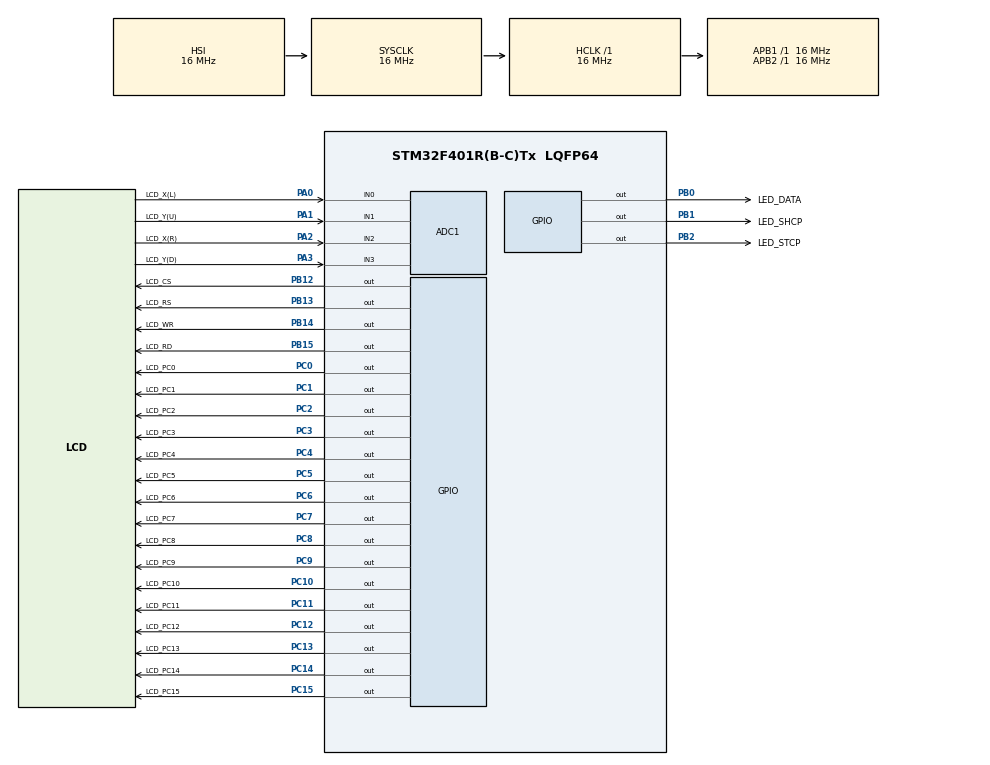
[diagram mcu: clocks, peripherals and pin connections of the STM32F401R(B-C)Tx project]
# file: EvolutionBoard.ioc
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ADC1.Channel-0\#ChannelRegularConversion=ADC_CHANNEL_0
ADC1.NbrOfConversionFlag=1
ADC1.Rank-0\#ChannelRegularConversion=1
ADC1.SamplingTime-0\#ChannelRegularConversion=ADC_SAMPLETIME_3CYCLES
ADC1.master=1
Dma.ADC1.0.Direction=DMA_PERIPH_TO_MEMORY
Dma.ADC1.0.FIFOMode=DMA_FIFOMODE_DISABLE
Dma.ADC1.0.Instance=DMA2_Stream0
Dma.ADC1.0.MemDataAlignment=DMA_MDATAALIGN_HALFWORD
Dma.ADC1.0.MemInc=DMA_MINC_ENABLE
Dma.ADC1.0.Mode=DMA_NORMAL
Dma.ADC1.0.PeriphDataAlignment=DMA_PDATAALIGN_HALFWORD
Dma.ADC1.0.PeriphInc=DMA_PINC_DISABLE
Dma.ADC1.0.Priority=DMA_PRIORITY_LOW
Dma.MEMTOMEM.1.Direction=DMA_MEMORY_TO_MEMORY
Dma.MEMTOMEM.1.FIFOMode=DMA_FIFOMODE_ENABLE
Dma.MEMTOMEM.1.FIFOThreshold=DMA_FIFO_THRESHOLD_FULL
Dma.MEMTOMEM.1.Instance=DMA2_Stream1
Dma.MEMTOMEM.1.MemBurst=DMA_MBURST_SINGLE
Dma.MEMTOMEM.1.MemDataAlignment=DMA_MDATAALIGN_BYTE
Dma.MEMTOMEM.1.MemInc=DMA_MINC_ENABLE
Dma.MEMTOMEM.1.Mode=DMA_NORMAL
Dma.MEMTOMEM.1.PeriphBurst=DMA_PBURST_SINGLE
Dma.MEMTOMEM.1.PeriphDataAlignment=DMA_PDATAALIGN_BYTE
Dma.MEMTOMEM.1.PeriphInc=DMA_PINC_ENABLE
Dma.MEMTOMEM.1.Priority=DMA_PRIORITY_LOW
Dma.Request0=ADC1
Dma.Request1=MEMTOMEM
Mcu.Family=STM32F4
Mcu.Name=STM32F401R(B-C)Tx
Mcu.Package=LQFP64
NVIC.DMA2_Stream0_IRQn=true\:5\:0\:false\:false\:true\:true\:false
NVIC.PriorityGroup=NVIC_PRIORITYGROUP_4
PA0-WKUP.GPIO_Label=LCD_X(L)
PA0-WKUP.Signal=ADCx_IN0
PA1.GPIO_Label=LCD_Y(U)
PA1.Signal=ADCx_IN1
PA13.Mode=Serial_Wire
PA13.Signal=SYS_JTMS-SWDIO
PA14.Mode=Serial_Wire
PA14.Signal=SYS_JTCK-SWCLK
PA2.GPIO_Label=LCD_X(R)
PA2.Signal=ADCx_IN2
PA3.GPIO_Label=LCD_Y(D)
PA3.Signal=ADCx_IN3
PB0.GPIO_Label=LED_DATA
PB0.Signal=GPIO_Output
PB1.GPIO_Label=LED_SHCP
PB1.Signal=GPIO_Output
PB12.GPIO_Label=LCD_CS
PB12.Signal=GPIO_Output
PB13.GPIO_Label=LCD_RS
PB13.Signal=GPIO_Output
PB14.GPIO_Label=LCD_WR
PB14.Signal=GPIO_Output
PB15.GPIO_Label=LCD_RD
PB15.Signal=GPIO_Output
PB2.GPIO_Label=LED_STCP
PB2.Signal=GPIO_Output
PC0.GPIO_Label=LCD_PC0
PC0.Signal=GPIO_Output
PC1.GPIO_Label=LCD_PC1
PC1.Signal=GPIO_Output
PC10.GPIO_Label=LCD_PC10
PC10.Signal=GPIO_Output
PC11.GPIO_Label=LCD_PC11
PC11.Signal=GPIO_Output
PC12.GPIO_Label=LCD_PC12
PC12.Signal=GPIO_Output
PC13-ANTI_TAMP.GPIO_Label=LCD_PC13
PC13-ANTI_TAMP.Signal=GPIO_Output
PC14-OSC32_IN.GPIO_Label=LCD_PC14
PC14-OSC32_IN.Signal=GPIO_Output
PC15-OSC32_OUT.GPIO_Label=LCD_PC15
PC15-OSC32_OUT.Signal=GPIO_Output
PC2.GPIO_Label=LCD_PC2
PC2.Signal=GPIO_Output
PC3.GPIO_Label=LCD_PC3
PC3.Signal=GPIO_Output
PC4.GPIO_Label=LCD_PC4
PC4.Signal=GPIO_Output
PC5.GPIO_Label=LCD_PC5
PC5.Signal=GPIO_Output
PC6.GPIO_Label=LCD_PC6
PC6.Signal=GPIO_Output
PC7.GPIO_Label=LCD_PC7
PC7.Signal=GPIO_Output
PC8.GPIO_Label=LCD_PC8
PC8.Signal=GPIO_Output
PC9.GPIO_Label=LCD_PC9
PC9.Signal=GPIO_Output
PH0\ -\ OSC_IN.Mode=HSE-External-Oscillator
PH0\ -\ OSC_IN.Signal=RCC_OSC_IN
PH1\ -\ OSC_OUT.Mode=HSE-External-Oscillator
PH1\ -\ OSC_OUT.Signal=RCC_OSC_OUT
ProjectManager.HeapSize=0x200
ProjectManager.StackSize=0x400
ProjectManager.TargetToolchain=TrueSTUDIO
RCC.48MHZClocksFreq_Value=48000000
RCC.AHBFreq_Value=16000000
RCC.APB1Freq_Value=16000000
RCC.APB2Freq_Value=16000000
RCC.CortexFreq_Value=16000000
RCC.HSE_VALUE=8000000
RCC.HSI_VALUE=16000000
RCC.LSE_VALUE=32768
RCC.PLLM=8
RCC.PLLN=240
RCC.PLLQ=5
RCC.PLLSourceVirtual=RCC_PLLSOURCE_HSE
RCC.SYSCLKFreq_VALUE=16000000
RCC.VCOOutputFreq_Value=240000000
SH.ADCx_IN0.0=ADC1_IN0,IN0
SH.ADCx_IN1.0=ADC1_IN1,IN1
SH.ADCx_IN2.0=ADC1_IN2,IN2
SH.ADCx_IN3.0=ADC1_IN3,IN3
board=custom

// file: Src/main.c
/* USER CODE BEGIN Header */
/**
  ******************************************************************************
  * @file           : main.c
  * @brief          : Main program body
  ******************************************************************************
  * @attention
  *
  * <h2><center>&copy; Copyright (c) 2019 STMicroelectronics.
  * All rights reserved.</center></h2>
  *
  * This software component is licensed by ST under BSD 3-Clause license,
  * the "License"; You may not use this file except in compliance with the
  * License. You may obtain a copy of the License at:
  *                        opensource.org/licenses/BSD-3-Clause
  *
  ******************************************************************************
  */
/* USER CODE END Header */

#include "main.h"

/* USER CODE BEGIN Includes */

#include "MainCpp.h"

/* USER CODE END Includes */

ADC_HandleTypeDef hadc1;
DMA_HandleTypeDef hdma_adc1;

DMA_HandleTypeDef hdma_memtomem_dma2_stream1;

void SystemClock_Config(void);
static void MX_GPIO_Init(void);
static void MX_DMA_Init(void);
static void MX_ADC1_Init(void);

/* USER CODE BEGIN 0 */

void MainCpp (void);

/* USER CODE END 0 */

int main(void)
{

  /* MCU Configuration--------------------------------------------------------*/

  /* Reset of all peripherals, Initializes the Flash interface and the Systick. */
  HAL_Init();

  /* Configure the system clock */
  SystemClock_Config();

  /* Initialize all configured peripherals */
  MX_GPIO_Init();
  MX_DMA_Init();
  MX_ADC1_Init();

  /* Infinite loop */
  while (1)
  {

    /* USER CODE BEGIN 3 */

	  MainCpp ();
  }
  /* USER CODE END 3 */
}

void SystemClock_Config(void)
{
  RCC_OscInitTypeDef RCC_OscInitStruct = {0};
  RCC_ClkInitTypeDef RCC_ClkInitStruct = {0};

  /** Configure the main internal regulator output voltage
  */
  __HAL_RCC_PWR_CLK_ENABLE();
  __HAL_PWR_VOLTAGESCALING_CONFIG(PWR_REGULATOR_VOLTAGE_SCALE2);
  /** Initializes the CPU, AHB and APB busses clocks
  */
  RCC_OscInitStruct.OscillatorType = RCC_OSCILLATORTYPE_HSI;
  RCC_OscInitStruct.HSIState = RCC_HSI_ON;
  RCC_OscInitStruct.HSICalibrationValue = RCC_HSICALIBRATION_DEFAULT;
  RCC_OscInitStruct.PLL.PLLState = RCC_PLL_NONE;
  if (HAL_RCC_OscConfig(&RCC_OscInitStruct) != HAL_OK)
  {
    Error_Handler();
  }
  /** Initializes the CPU, AHB and APB busses clocks
  */
  RCC_ClkInitStruct.ClockType = RCC_CLOCKTYPE_HCLK|RCC_CLOCKTYPE_SYSCLK
                              |RCC_CLOCKTYPE_PCLK1|RCC_CLOCKTYPE_PCLK2;
  RCC_ClkInitStruct.SYSCLKSource = RCC_SYSCLKSOURCE_HSI;
  RCC_ClkInitStruct.AHBCLKDivider = RCC_SYSCLK_DIV1;
  RCC_ClkInitStruct.APB1CLKDivider = RCC_HCLK_DIV1;
  RCC_ClkInitStruct.APB2CLKDivider = RCC_HCLK_DIV1;

  if (HAL_RCC_ClockConfig(&RCC_ClkInitStruct, FLASH_LATENCY_0) != HAL_OK)
  {
    Error_Handler();
  }
}

static void MX_ADC1_Init(void)
{

  ADC_ChannelConfTypeDef sConfig = {0};

  /** Configure the global features of the ADC (Clock, Resolution, Data Alignment and number of conversion)
  */
  hadc1.Instance = ADC1;
  hadc1.Init.ClockPrescaler = ADC_CLOCK_SYNC_PCLK_DIV2;
  hadc1.Init.Resolution = ADC_RESOLUTION_12B;
  hadc1.Init.ScanConvMode = DISABLE;
  hadc1.Init.ContinuousConvMode = DISABLE;
  hadc1.Init.DiscontinuousConvMode = DISABLE;
  hadc1.Init.ExternalTrigConvEdge = ADC_EXTERNALTRIGCONVEDGE_NONE;
  hadc1.Init.ExternalTrigConv = ADC_SOFTWARE_START;
  hadc1.Init.DataAlign = ADC_DATAALIGN_RIGHT;
  hadc1.Init.NbrOfConversion = 1;
  hadc1.Init.DMAContinuousRequests = DISABLE;
  hadc1.Init.EOCSelection = ADC_EOC_SINGLE_CONV;
  if (HAL_ADC_Init(&hadc1) != HAL_OK)
  {
    Error_Handler();
  }
  /** Configure for the selected ADC regular channel its corresponding rank in the sequencer and its sample time.
  */
  sConfig.Channel = ADC_CHANNEL_0;
  sConfig.Rank = 1;
  sConfig.SamplingTime = ADC_SAMPLETIME_3CYCLES;
  if (HAL_ADC_ConfigChannel(&hadc1, &sConfig) != HAL_OK)
  {
    Error_Handler();
  }

}

static void MX_DMA_Init(void)
{

  /* DMA controller clock enable */
  __HAL_RCC_DMA2_CLK_ENABLE();

  /* Configure DMA request hdma_memtomem_dma2_stream1 on DMA2_Stream1 */
  hdma_memtomem_dma2_stream1.Instance = DMA2_Stream1;
  hdma_memtomem_dma2_stream1.Init.Channel = DMA_CHANNEL_0;
  hdma_memtomem_dma2_stream1.Init.Direction = DMA_MEMORY_TO_MEMORY;
  hdma_memtomem_dma2_stream1.Init.PeriphInc = DMA_PINC_ENABLE;
  hdma_memtomem_dma2_stream1.Init.MemInc = DMA_MINC_ENABLE;
  hdma_memtomem_dma2_stream1.Init.PeriphDataAlignment = DMA_PDATAALIGN_BYTE;
  hdma_memtomem_dma2_stream1.Init.MemDataAlignment = DMA_MDATAALIGN_BYTE;
  hdma_memtomem_dma2_stream1.Init.Mode = DMA_NORMAL;
  hdma_memtomem_dma2_stream1.Init.Priority = DMA_PRIORITY_LOW;
  hdma_memtomem_dma2_stream1.Init.FIFOMode = DMA_FIFOMODE_ENABLE;
  hdma_memtomem_dma2_stream1.Init.FIFOThreshold = DMA_FIFO_THRESHOLD_FULL;
  hdma_memtomem_dma2_stream1.Init.MemBurst = DMA_MBURST_SINGLE;
  hdma_memtomem_dma2_stream1.Init.PeriphBurst = DMA_PBURST_SINGLE;
  if (HAL_DMA_Init(&hdma_memtomem_dma2_stream1) != HAL_OK)
  {
    Error_Handler( );
  }

  /* DMA interrupt init */
  /* DMA2_Stream0_IRQn interrupt configuration */
  HAL_NVIC_SetPriority(DMA2_Stream0_IRQn, 5, 0);
  HAL_NVIC_EnableIRQ(DMA2_Stream0_IRQn);

}

static void MX_GPIO_Init(void)
{
  GPIO_InitTypeDef GPIO_InitStruct = {0};

  /* GPIO Ports Clock Enable */
  __HAL_RCC_GPIOC_CLK_ENABLE();
  __HAL_RCC_GPIOH_CLK_ENABLE();
  __HAL_RCC_GPIOA_CLK_ENABLE();
  __HAL_RCC_GPIOB_CLK_ENABLE();

  /*Configure GPIO pin Output Level */
  HAL_GPIO_WritePin(GPIOC, LCD_PC13_Pin|LCD_PC14_Pin|LCD_PC15_Pin|LCD_PC0_Pin
                          |LCD_PC1_Pin|LCD_PC2_Pin|LCD_PC3_Pin|LCD_PC4_Pin
                          |LCD_PC5_Pin|LCD_PC6_Pin|LCD_PC7_Pin|LCD_PC8_Pin
                          |LCD_PC9_Pin|LCD_PC10_Pin|LCD_PC11_Pin|LCD_PC12_Pin, GPIO_PIN_RESET);

  /*Configure GPIO pin Output Level */
  HAL_GPIO_WritePin(GPIOB, LED_DATA_Pin|LED_SHCP_Pin|LED_STCP_Pin|LCD_CS_Pin
                          |LCD_RS_Pin|LCD_WR_Pin|LCD_RD_Pin, GPIO_PIN_RESET);

  /*Configure GPIO pins : LCD_PC13_Pin LCD_PC14_Pin LCD_PC15_Pin LCD_PC0_Pin
                           LCD_PC1_Pin LCD_PC2_Pin LCD_PC3_Pin LCD_PC4_Pin
                           LCD_PC5_Pin LCD_PC6_Pin LCD_PC7_Pin LCD_PC8_Pin
                           LCD_PC9_Pin LCD_PC10_Pin LCD_PC11_Pin LCD_PC12_Pin */
  GPIO_InitStruct.Pin = LCD_PC13_Pin|LCD_PC14_Pin|LCD_PC15_Pin|LCD_PC0_Pin
                          |LCD_PC1_Pin|LCD_PC2_Pin|LCD_PC3_Pin|LCD_PC4_Pin
                          |LCD_PC5_Pin|LCD_PC6_Pin|LCD_PC7_Pin|LCD_PC8_Pin
                          |LCD_PC9_Pin|LCD_PC10_Pin|LCD_PC11_Pin|LCD_PC12_Pin;
  GPIO_InitStruct.Mode = GPIO_MODE_OUTPUT_PP;
  GPIO_InitStruct.Pull = GPIO_NOPULL;
  GPIO_InitStruct.Speed = GPIO_SPEED_FREQ_LOW;
  HAL_GPIO_Init(GPIOC, &GPIO_InitStruct);

  /*Configure GPIO pins : LED_DATA_Pin LED_SHCP_Pin LED_STCP_Pin LCD_CS_Pin
                           LCD_RS_Pin LCD_WR_Pin LCD_RD_Pin */
  GPIO_InitStruct.Pin = LED_DATA_Pin|LED_SHCP_Pin|LED_STCP_Pin|LCD_CS_Pin
                          |LCD_RS_Pin|LCD_WR_Pin|LCD_RD_Pin;
  GPIO_InitStruct.Mode = GPIO_MODE_OUTPUT_PP;
  GPIO_InitStruct.Pull = GPIO_NOPULL;
  GPIO_InitStruct.Speed = GPIO_SPEED_FREQ_LOW;
  HAL_GPIO_Init(GPIOB, &GPIO_InitStruct);

}

void Error_Handler(void)
{
}

/************************ (C) COPYRIGHT STMicroelectronics *****END OF FILE****/
